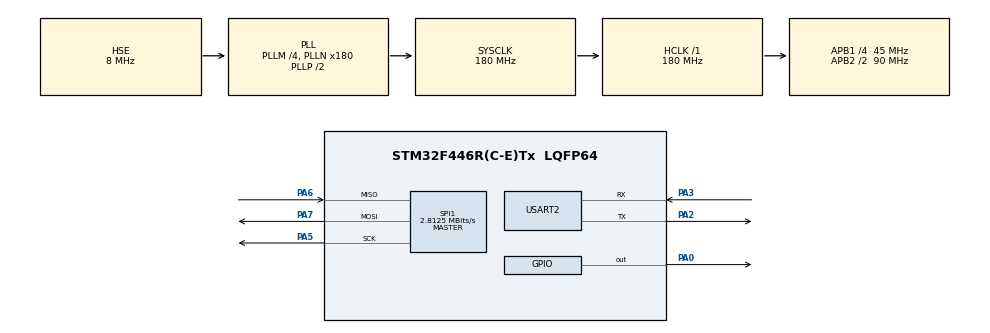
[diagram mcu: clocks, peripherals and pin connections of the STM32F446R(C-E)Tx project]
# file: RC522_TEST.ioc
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Mcu.Family=STM32F4
Mcu.Name=STM32F446R(C-E)Tx
Mcu.Package=LQFP64
NVIC.PriorityGroup=NVIC_PRIORITYGROUP_4
PA0-WKUP.Signal=GPIO_Output
PA13.Mode=Serial_Wire
PA13.Signal=SYS_JTMS-SWDIO
PA14.Mode=Serial_Wire
PA14.Signal=SYS_JTCK-SWCLK
PA2.Mode=Asynchronous
PA2.Signal=USART2_TX
PA3.Mode=Asynchronous
PA3.Signal=USART2_RX
PA5.Mode=Full_Duplex_Master
PA5.Signal=SPI1_SCK
PA6.Mode=Full_Duplex_Master
PA6.Signal=SPI1_MISO
PA7.Mode=Full_Duplex_Master
PA7.Signal=SPI1_MOSI
PH0-OSC_IN.Mode=HSE-External-Oscillator
PH0-OSC_IN.Signal=RCC_OSC_IN
PH1-OSC_OUT.Mode=HSE-External-Oscillator
PH1-OSC_OUT.Signal=RCC_OSC_OUT
ProjectManager.HeapSize=0x200
ProjectManager.StackSize=0x400
ProjectManager.TargetToolchain=STM32CubeIDE
RCC.AHBFreq_Value=180000000
RCC.APB1CLKDivider=RCC_HCLK_DIV4
RCC.APB1Freq_Value=45000000
RCC.APB1TimFreq_Value=90000000
RCC.APB2CLKDivider=RCC_HCLK_DIV2
RCC.APB2Freq_Value=90000000
RCC.APB2TimFreq_Value=180000000
RCC.CortexFreq_Value=180000000
RCC.HCLKFreq_Value=180000000
RCC.HSE_VALUE=8000000
RCC.PLLM=4
RCC.PLLN=180
RCC.PLLSourceVirtual=RCC_PLLSOURCE_HSE
RCC.SYSCLKFreq_VALUE=180000000
RCC.SYSCLKSource=RCC_SYSCLKSOURCE_PLLCLK
RCC.USBFreq_Value=180000000
RCC.VCOOutputFreq_Value=360000000
SPI1.BaudRatePrescaler=SPI_BAUDRATEPRESCALER_32
SPI1.CalculateBaudRate=2.8125 MBits/s
SPI1.Direction=SPI_DIRECTION_2LINES
SPI1.Mode=SPI_MODE_MASTER
SPI1.VirtualType=VM_MASTER
USART2.VirtualMode=VM_ASYNC
board=custom

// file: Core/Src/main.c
/* USER CODE BEGIN Header */
/**
  ******************************************************************************
  * @file           : main.c
  * @brief          : Main program body
  ******************************************************************************
  * @attention
  *
  * Copyright (c) 2023 STMicroelectronics.
  * All rights reserved.
  *
  * This software is licensed under terms that can be found in the LICENSE file
  * in the root directory of this software component.
  * If no LICENSE file comes with this software, it is provided AS-IS.
  *
  ******************************************************************************
  */
/* USER CODE END Header */
#include "main.h"

/* USER CODE BEGIN Includes */
#include "bsp_mfrc522.h"
#include "driver_mfrc522.h"
/* USER CODE END Includes */

 SPI_HandleTypeDef hspi1;

UART_HandleTypeDef huart2;

void SystemClock_Config(void);
static void MX_GPIO_Init(void);
static void MX_SPI1_Init(void);
static void MX_USART2_UART_Init(void);

/* USER CODE BEGIN 0 */
uint8_t data[15];

/* USER CODE END 0 */

int main(void)
{

  /* MCU Configuration--------------------------------------------------------*/

  /* Reset of all peripherals, Initializes the Flash interface and the Systick. */
  HAL_Init();

  /* Configure the system clock */
  SystemClock_Config();

  /* Initialize all configured peripherals */
  MX_GPIO_Init();
  MX_SPI1_Init();
  MX_USART2_UART_Init();
  /* USER CODE BEGIN 2 */
  drv_mfrc522_init();

  uint8_t send_data[] = "Hello";
  bsp_mfrc522_write_address(63, send_data);
  /* USER CODE END 2 */

  /* Infinite loop */
  while (1)
  {

    /* USER CODE BEGIN 3 */
	  if( drv_mfrc522_read_id_card(data) == drv_mfrc522_ok)
	     	HAL_UART_Transmit(&huart2, (uint8_t*) "Error\r\n", 7, 100);

	     HAL_Delay(1000);
  }
  /* USER CODE END 3 */
}

void SystemClock_Config(void)
{
  RCC_OscInitTypeDef RCC_OscInitStruct = {0};
  RCC_ClkInitTypeDef RCC_ClkInitStruct = {0};

  /** Configure the main internal regulator output voltage
  */
  __HAL_RCC_PWR_CLK_ENABLE();
  __HAL_PWR_VOLTAGESCALING_CONFIG(PWR_REGULATOR_VOLTAGE_SCALE1);

  /** Initializes the RCC Oscillators according to the specified parameters
  * in the RCC_OscInitTypeDef structure.
  */
  RCC_OscInitStruct.OscillatorType = RCC_OSCILLATORTYPE_HSE;
  RCC_OscInitStruct.HSEState = RCC_HSE_ON;
  RCC_OscInitStruct.PLL.PLLState = RCC_PLL_ON;
  RCC_OscInitStruct.PLL.PLLSource = RCC_PLLSOURCE_HSE;
  RCC_OscInitStruct.PLL.PLLM = 4;
  RCC_OscInitStruct.PLL.PLLN = 180;
  RCC_OscInitStruct.PLL.PLLP = RCC_PLLP_DIV2;
  RCC_OscInitStruct.PLL.PLLQ = 2;
  RCC_OscInitStruct.PLL.PLLR = 2;
  if (HAL_RCC_OscConfig(&RCC_OscInitStruct) != HAL_OK)
  {
    Error_Handler();
  }

  /** Activate the Over-Drive mode
  */
  if (HAL_PWREx_EnableOverDrive() != HAL_OK)
  {
    Error_Handler();
  }

  /** Initializes the CPU, AHB and APB buses clocks
  */
  RCC_ClkInitStruct.ClockType = RCC_CLOCKTYPE_HCLK|RCC_CLOCKTYPE_SYSCLK
                              |RCC_CLOCKTYPE_PCLK1|RCC_CLOCKTYPE_PCLK2;
  RCC_ClkInitStruct.SYSCLKSource = RCC_SYSCLKSOURCE_PLLCLK;
  RCC_ClkInitStruct.AHBCLKDivider = RCC_SYSCLK_DIV1;
  RCC_ClkInitStruct.APB1CLKDivider = RCC_HCLK_DIV4;
  RCC_ClkInitStruct.APB2CLKDivider = RCC_HCLK_DIV2;

  if (HAL_RCC_ClockConfig(&RCC_ClkInitStruct, FLASH_LATENCY_5) != HAL_OK)
  {
    Error_Handler();
  }
}

static void MX_SPI1_Init(void)
{

  /* SPI1 parameter configuration*/
  hspi1.Instance = SPI1;
  hspi1.Init.Mode = SPI_MODE_MASTER;
  hspi1.Init.Direction = SPI_DIRECTION_2LINES;
  hspi1.Init.DataSize = SPI_DATASIZE_8BIT;
  hspi1.Init.CLKPolarity = SPI_POLARITY_LOW;
  hspi1.Init.CLKPhase = SPI_PHASE_1EDGE;
  hspi1.Init.NSS = SPI_NSS_SOFT;
  hspi1.Init.BaudRatePrescaler = SPI_BAUDRATEPRESCALER_32;
  hspi1.Init.FirstBit = SPI_FIRSTBIT_MSB;
  hspi1.Init.TIMode = SPI_TIMODE_DISABLE;
  hspi1.Init.CRCCalculation = SPI_CRCCALCULATION_DISABLE;
  hspi1.Init.CRCPolynomial = 10;
  if (HAL_SPI_Init(&hspi1) != HAL_OK)
  {
    Error_Handler();
  }

}

static void MX_USART2_UART_Init(void)
{

  huart2.Instance = USART2;
  huart2.Init.BaudRate = 115200;
  huart2.Init.WordLength = UART_WORDLENGTH_8B;
  huart2.Init.StopBits = UART_STOPBITS_1;
  huart2.Init.Parity = UART_PARITY_NONE;
  huart2.Init.Mode = UART_MODE_TX_RX;
  huart2.Init.HwFlowCtl = UART_HWCONTROL_NONE;
  huart2.Init.OverSampling = UART_OVERSAMPLING_16;
  if (HAL_UART_Init(&huart2) != HAL_OK)
  {
    Error_Handler();
  }

}

static void MX_GPIO_Init(void)
{
  GPIO_InitTypeDef GPIO_InitStruct = {0};

  /* GPIO Ports Clock Enable */
  __HAL_RCC_GPIOH_CLK_ENABLE();
  __HAL_RCC_GPIOA_CLK_ENABLE();

  /*Configure GPIO pin Output Level */
  HAL_GPIO_WritePin(GPIOA, GPIO_PIN_0, GPIO_PIN_RESET);

  /*Configure GPIO pin : PA0 */
  GPIO_InitStruct.Pin = GPIO_PIN_0;
  GPIO_InitStruct.Mode = GPIO_MODE_OUTPUT_PP;
  GPIO_InitStruct.Pull = GPIO_NOPULL;
  GPIO_InitStruct.Speed = GPIO_SPEED_FREQ_LOW;
  HAL_GPIO_Init(GPIOA, &GPIO_InitStruct);

}

void Error_Handler(void)
{
  __disable_irq();
  while (1)
  {
  }
}
